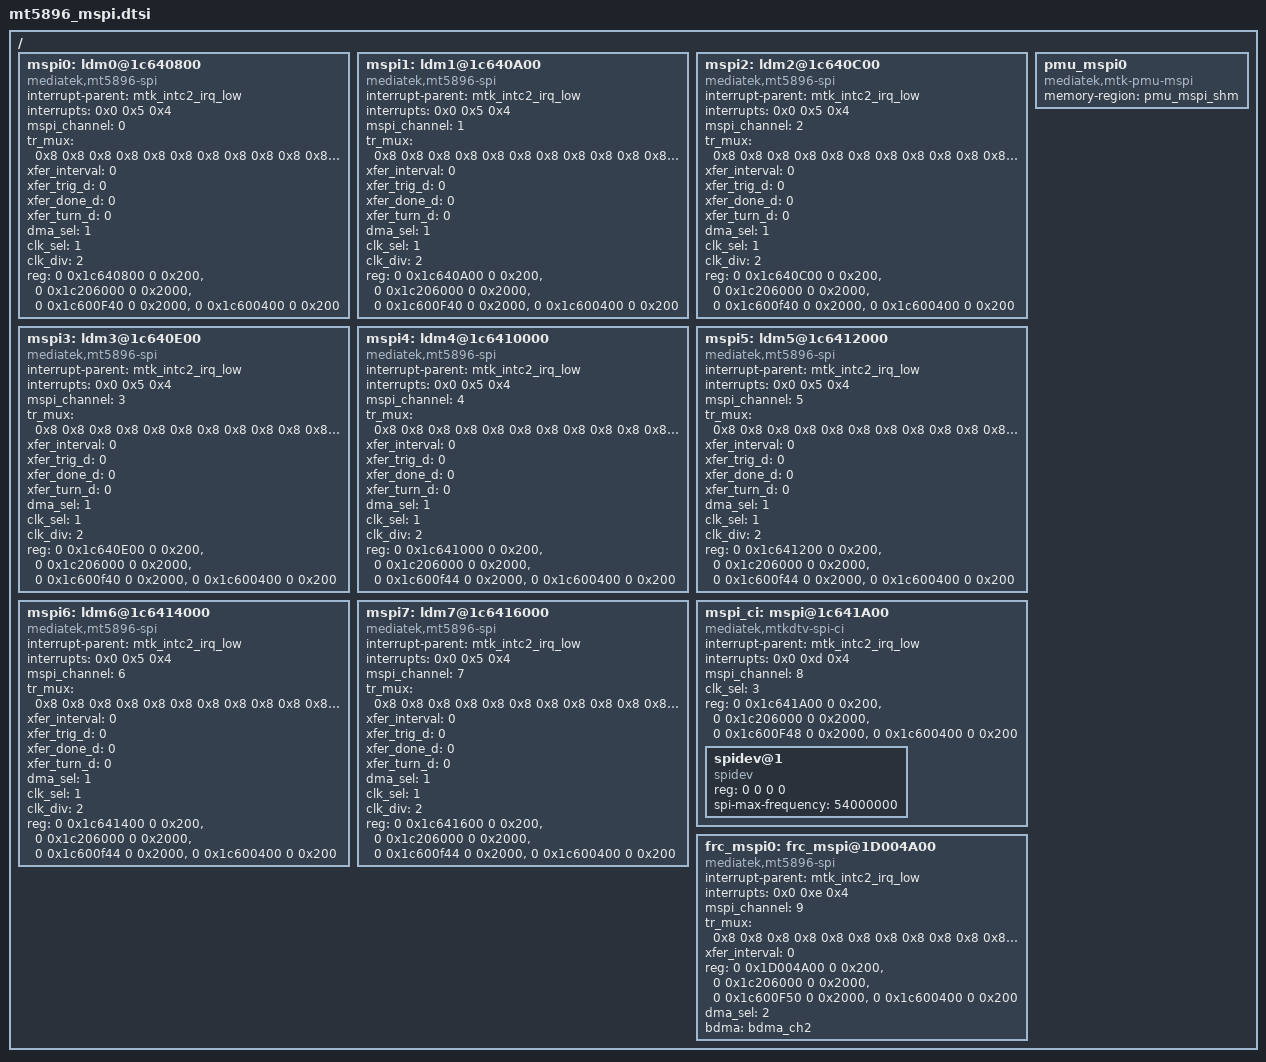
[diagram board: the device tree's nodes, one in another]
// SPDX-License-Identifier: (GPL-2.0 OR BSD-3-Clause)
/*
 * Copyright (c) 2021 MediaTek Inc.
 */

/ {
	mspi0:ldm0@1c640800 {
		compatible = "mediatek,mt5896-spi";
		#address-cells = <2>;
		#size-cells = <2>;
		interrupt-parent = <&mtk_intc2_irq_low>;
		interrupts = <0x0 0x5 0x4>;
		mspi_channel = <0>;
		tr_mux = /bits/8<0x8 0x8 0x8 0x8 0x8 0x8 0x8 0x8
							0x8 0x8 0x8 0x8 0x8 0x8 0x8 0x8
							0x8 0x8 0x8 0x8 0x8 0x8 0x8 0x8
							0x8 0x8 0x8 0x8 0x8 0x8 0x8 0x8>;
		xfer_interval = <0>;
		xfer_trig_d = <0>;
		xfer_done_d = <0>;
		xfer_turn_d = <0>;
		dma_sel = <1>;
		clk_sel = <1>;
		clk_div = <2>;
		reg = <0 0x1c640800 0 0x200>,<0 0x1c206000 0 0x2000>,
		<0 0x1c600F40 0 0x2000>,<0 0x1c600400 0 0x200>;
	};
	mspi1:ldm1@1c640A00 {
		compatible = "mediatek,mt5896-spi";
		#address-cells = <2>;
		#size-cells = <2>;
		interrupt-parent = <&mtk_intc2_irq_low>;
		interrupts = <0x0 0x5 0x4>;
		mspi_channel = <1>;
		tr_mux = /bits/8<0x8 0x8 0x8 0x8 0x8 0x8 0x8 0x8
							0x8 0x8 0x8 0x8 0x8 0x8 0x8 0x8
							0x8 0x8 0x8 0x8 0x8 0x8 0x8 0x8
							0x8 0x8 0x8 0x8 0x8 0x8 0x8 0x8>;
		xfer_interval = <0>;
		xfer_trig_d = <0>;
		xfer_done_d = <0>;
		xfer_turn_d = <0>;
		dma_sel = <1>;
		clk_sel = <1>;
		clk_div = <2>;
		reg = <0 0x1c640A00 0 0x200>,<0 0x1c206000 0 0x2000>,
		<0 0x1c600F40 0 0x2000>,<0 0x1c600400 0 0x200>;
	};
	mspi2:ldm2@1c640C00 {
		compatible = "mediatek,mt5896-spi";
		#address-cells = <2>;
		#size-cells = <2>;
		interrupt-parent = <&mtk_intc2_irq_low>;
		interrupts = <0x0 0x5 0x4>;
		mspi_channel = <2>;
		tr_mux = /bits/8<0x8 0x8 0x8 0x8 0x8 0x8 0x8 0x8
							0x8 0x8 0x8 0x8 0x8 0x8 0x8 0x8
							0x8 0x8 0x8 0x8 0x8 0x8 0x8 0x8
							0x8 0x8 0x8 0x8 0x8 0x8 0x8 0x8>;
		xfer_interval = <0>;
		xfer_trig_d = <0>;
		xfer_done_d = <0>;
		xfer_turn_d = <0>;
		dma_sel = <1>;
		clk_sel = <1>;
		clk_div = <2>;
		reg = <0 0x1c640C00 0 0x200>,<0 0x1c206000 0 0x2000>,
		<0 0x1c600f40 0 0x2000>,<0 0x1c600400 0 0x200>;
	};
	mspi3:ldm3@1c640E00 {
		compatible = "mediatek,mt5896-spi";
		#address-cells = <2>;
		#size-cells = <2>;
		interrupt-parent = <&mtk_intc2_irq_low>;
		interrupts = <0x0 0x5 0x4>;
		mspi_channel = < 3 >;
		tr_mux = /bits/8<0x8 0x8 0x8 0x8 0x8 0x8 0x8 0x8
							0x8 0x8 0x8 0x8 0x8 0x8 0x8 0x8
							0x8 0x8 0x8 0x8 0x8 0x8 0x8 0x8
							0x8 0x8 0x8 0x8 0x8 0x8 0x8 0x8>;
		xfer_interval = <0>;
		xfer_trig_d = <0>;
		xfer_done_d = <0>;
		xfer_turn_d = <0>;
		dma_sel = <1>;
		clk_sel = <1>;
		clk_div = <2>;
		reg = <0 0x1c640E00 0 0x200>,<0 0x1c206000 0 0x2000>,
		<0 0x1c600f40 0 0x2000>,<0 0x1c600400 0 0x200>;
	};
	mspi4:ldm4@1c6410000 {
		compatible = "mediatek,mt5896-spi";
		#address-cells = <2>;
		#size-cells = <2>;
		interrupt-parent = <&mtk_intc2_irq_low>;
		interrupts = <0x0 0x5 0x4>;
		mspi_channel = <4>;
		tr_mux = /bits/8<0x8 0x8 0x8 0x8 0x8 0x8 0x8 0x8
							0x8 0x8 0x8 0x8 0x8 0x8 0x8 0x8
							0x8 0x8 0x8 0x8 0x8 0x8 0x8 0x8
							0x8 0x8 0x8 0x8 0x8 0x8 0x8 0x8>;
		xfer_interval = <0>;
		xfer_trig_d = <0>;
		xfer_done_d = <0>;
		xfer_turn_d = <0>;
		dma_sel = <1>;
		clk_sel = <1>;
		clk_div = <2>;
		reg = <0 0x1c641000 0 0x200>,<0 0x1c206000 0 0x2000>,
		<0 0x1c600f44 0 0x2000>,<0 0x1c600400 0 0x200>;
	};
	mspi5:ldm5@1c6412000 {
		compatible = "mediatek,mt5896-spi";
		#address-cells = <2>;
		#size-cells = <2>;
		interrupt-parent = <&mtk_intc2_irq_low>;
		interrupts = <0x0 0x5 0x4>;
		mspi_channel = <5>;
		tr_mux = /bits/8<0x8 0x8 0x8 0x8 0x8 0x8 0x8 0x8
							0x8 0x8 0x8 0x8 0x8 0x8 0x8 0x8
							0x8 0x8 0x8 0x8 0x8 0x8 0x8 0x8
							0x8 0x8 0x8 0x8 0x8 0x8 0x8 0x8>;
		xfer_interval = <0>;
		xfer_trig_d = <0>;
		xfer_done_d = <0>;
		xfer_turn_d = <0>;
		dma_sel = <1>;
		clk_sel = <1>;
		clk_div = <2>;
		reg = <0 0x1c641200 0 0x200>,<0 0x1c206000 0 0x2000>,
		<0 0x1c600f44 0 0x2000>,<0 0x1c600400 0 0x200>;
	};
	mspi6:ldm6@1c6414000 {
		compatible = "mediatek,mt5896-spi";
		#address-cells = <2>;
		#size-cells = <2>;
		interrupt-parent = <&mtk_intc2_irq_low>;
		interrupts = <0x0 0x5 0x4>;
		mspi_channel = <6>;
		tr_mux = /bits/8<0x8 0x8 0x8 0x8 0x8 0x8 0x8 0x8
							0x8 0x8 0x8 0x8 0x8 0x8 0x8 0x8
							0x8 0x8 0x8 0x8 0x8 0x8 0x8 0x8
							0x8 0x8 0x8 0x8 0x8 0x8 0x8 0x8>;
		xfer_interval = <0>;
		xfer_trig_d = <0>;
		xfer_done_d = <0>;
		xfer_turn_d = <0>;
		dma_sel = <1>;
		clk_sel = <1>;
		clk_div = <2>;
		reg = <0 0x1c641400 0 0x200>,<0 0x1c206000 0 0x2000>,
		<0 0x1c600f44 0 0x2000>,<0 0x1c600400 0 0x200>;
	};
	mspi7:ldm7@1c6416000 {
		compatible = "mediatek,mt5896-spi";
		#address-cells = <2>;
		#size-cells = <2>;
		interrupt-parent = <&mtk_intc2_irq_low>;
		interrupts = <0x0 0x5 0x4>;
		mspi_channel = <7>;
		tr_mux = /bits/8<0x8 0x8 0x8 0x8 0x8 0x8 0x8 0x8
							0x8 0x8 0x8 0x8 0x8 0x8 0x8 0x8
							0x8 0x8 0x8 0x8 0x8 0x8 0x8 0x8
							0x8 0x8 0x8 0x8 0x8 0x8 0x8 0x8>;
		xfer_interval = <0>;
		xfer_trig_d = <0>;
		xfer_done_d = <0>;
		xfer_turn_d = <0>;
		dma_sel = <1>;
		clk_sel = <1>;
		clk_div = <2>;
		reg = <0 0x1c641600 0 0x200>,<0 0x1c206000 0 0x2000>,
		<0 0x1c600f44 0 0x2000>,<0 0x1c600400 0 0x200>;
	};
	mspi_ci:mspi@1c641A00 {
		compatible = "mediatek,mtkdtv-spi-ci";
		#address-cells = <2>;
		#size-cells = <2>;
		interrupt-parent = <&mtk_intc2_irq_low>;
		interrupts = <0x0 0xd 0x4>;
		mspi_channel = <8>;
		clk_sel = <3>;
		reg = <0 0x1c641A00 0 0x200>,<0 0x1c206000 0 0x2000>,
				<0 0x1c600F48 0 0x2000>,<0 0x1c600400 0 0x200>;
		spidev@1{
			compatible = "spidev";
			reg = <0 0 0 0>;
			spi-max-frequency = <54000000>;
			};
	};
	pmu_mspi0: pmu_mspi0 {
		compatible = "mediatek,mtk-pmu-mspi";
		memory-region = <&pmu_mspi_shm>;
		#address-cells = <2>;
		#size-cells = <2>;
		status = "okay";
	};
	frc_mspi0:frc_mspi@1D004A00 {
		compatible = "mediatek,mt5896-spi";
		#address-cells = <2>;
		#size-cells = <2>;
		interrupt-parent = <&mtk_intc2_irq_low>;
		interrupts = <0x0 0xe 0x4>;
		mspi_channel = <9>;
		tr_mux = /bits/8<0x8 0x8 0x8 0x8 0x8 0x8 0x8 0x8
							0x8 0x8 0x8 0x8 0x8 0x8 0x8 0x8
							0x8 0x8 0x8 0x8 0x8 0x8 0x8 0x8
							0x8 0x8 0x8 0x8 0x8 0x8 0x8 0x8>;
		xfer_interval = <0>;
		reg = <0 0x1D004A00 0 0x200>,<0 0x1c206000 0 0x2000>,
				<0 0x1c600F50 0 0x2000>,<0 0x1c600400 0 0x200>;
		dma_sel = <2>;
		bdma = "bdma_ch2";
	};
};
